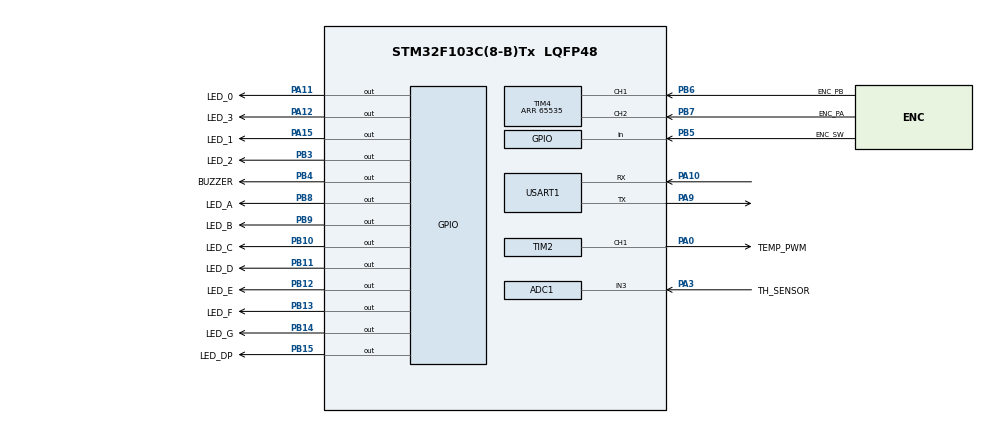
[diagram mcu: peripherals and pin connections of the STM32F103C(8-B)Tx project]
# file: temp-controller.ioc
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ADC1.Channel-2\#ChannelRegularConversion=ADC_CHANNEL_3
ADC1.ContinuousConvMode=ENABLE
ADC1.NbrOfConversion=1
ADC1.NbrOfConversionFlag=1
ADC1.Rank-2\#ChannelRegularConversion=1
ADC1.SamplingTime-2\#ChannelRegularConversion=ADC_SAMPLETIME_1CYCLE_5
ADC1.master=1
Mcu.Family=STM32F1
Mcu.Name=STM32F103C(8-B)Tx
Mcu.Package=LQFP48
NVIC.ADC1_2_IRQn=true\:0\:0\:false\:false\:true\:true\:true
NVIC.PriorityGroup=NVIC_PRIORITYGROUP_4
NVIC.TIM4_IRQn=true\:0\:0\:false\:false\:true\:true\:true
PA0-WKUP.GPIO_Label=TEMP_PWM
PA0-WKUP.Signal=S_TIM2_CH1_ETR
PA10.Mode=Asynchronous
PA10.Signal=USART1_RX
PA11.GPIO_Label=LED_0
PA11.Signal=GPIO_Output
PA12.GPIO_Label=LED_3
PA12.Signal=GPIO_Output
PA13.Mode=Serial_Wire
PA13.Signal=SYS_JTMS-SWDIO
PA14.Mode=Serial_Wire
PA14.Signal=SYS_JTCK-SWCLK
PA15.GPIO_Label=LED_1
PA15.Signal=GPIO_Output
PA3.GPIO_Label=TH_SENSOR
PA3.Signal=ADCx_IN3
PA9.Mode=Asynchronous
PA9.Signal=USART1_TX
PB10.GPIO_Label=LED_C
PB10.Signal=GPIO_Output
PB11.GPIO_Label=LED_D
PB11.Signal=GPIO_Output
PB12.GPIO_Label=LED_E
PB12.Signal=GPIO_Output
PB13.GPIO_Label=LED_F
PB13.Signal=GPIO_Output
PB14.GPIO_Label=LED_G
PB14.Signal=GPIO_Output
PB15.GPIO_Label=LED_DP
PB15.Signal=GPIO_Output
PB3.GPIO_Label=LED_2
PB3.Signal=GPIO_Output
PB4.GPIO_Label=BUZZER
PB4.Signal=GPIO_Output
PB5.GPIO_Label=ENC_SW
PB5.Signal=GPIO_Input
PB6.GPIO_Label=ENC_PB
PB6.GPIO_PuPd=GPIO_PULLUP
PB6.Signal=S_TIM4_CH1
PB7.GPIO_Label=ENC_PA
PB7.GPIO_PuPd=GPIO_PULLUP
PB7.Signal=S_TIM4_CH2
PB8.GPIO_Label=LED_A
PB8.Signal=GPIO_Output
PB9.GPIO_Label=LED_B
PB9.Signal=GPIO_Output
ProjectManager.HeapSize=0x200
ProjectManager.StackSize=0x400
ProjectManager.TargetToolchain=SW4STM32
RCC.APB1Freq_Value=8000000
RCC.APB2Freq_Value=8000000
SH.ADCx_IN3.0=ADC1_IN3,IN3
SH.S_TIM2_CH1_ETR.0=TIM2_CH1,PWM Generation1 CH1
SH.S_TIM4_CH1.0=TIM4_CH1,Encoder_Interface
SH.S_TIM4_CH2.0=TIM4_CH2,Encoder_Interface
TIM2.Channel-PWM\ Generation1\ CH1=TIM_CHANNEL_1
TIM2.Period=999
TIM2.Prescaler=79
TIM4.EncoderMode=TIM_ENCODERMODE_TI12
TIM4.Period=65535
USART1.VirtualMode=VM_ASYNC
VP_TIM2_VS_ClockSourceINT.Mode=Internal
board=custom

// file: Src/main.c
/* USER CODE BEGIN Header */
/**
  ******************************************************************************
  * @file           : main.c
  * @brief          : Main program body
  ******************************************************************************
  * @attention
  *
  * <h2><center>&copy; Copyright (c) 2019 STMicroelectronics.
  * All rights reserved.</center></h2>
  *
  * This software component is licensed by ST under BSD 3-Clause license,
  * the "License"; You may not use this file except in compliance with the
  * License. You may obtain a copy of the License at:
  *                        opensource.org/licenses/BSD-3-Clause
  *
  ******************************************************************************
  */
/* USER CODE END Header */

#include "main.h"
#include "adc.h"
#include "tim.h"
#include "usart.h"
#include "gpio.h"

/* USER CODE BEGIN Includes */
#include <Src/user_code/user_main.h>
/* USER CODE END Includes */

void SystemClock_Config(void);

int main(void)
{

  /* MCU Configuration--------------------------------------------------------*/

  /* Reset of all peripherals, Initializes the Flash interface and the Systick. */
  HAL_Init();

  /* Configure the system clock */
  SystemClock_Config();

  /* Initialize all configured peripherals */
  MX_GPIO_Init();
  MX_ADC1_Init();
  MX_TIM2_Init();
  MX_TIM4_Init();
  MX_USART1_UART_Init();
  /* USER CODE BEGIN 2 */

  user_main();

  /* USER CODE END 2 */

  /* Infinite loop */
  /* USER CODE BEGIN WHILE */
  while (1)
  {
//	  for(float i = 0; i <=99.99; i+=0.01){
//		  led_show(i);
//		  HAL_Delay(10);
//	  }
    /* USER CODE END WHILE */

  }
}

void SystemClock_Config(void)
{
  RCC_OscInitTypeDef RCC_OscInitStruct = {0};
  RCC_ClkInitTypeDef RCC_ClkInitStruct = {0};
  RCC_PeriphCLKInitTypeDef PeriphClkInit = {0};

  /** Initializes the CPU, AHB and APB busses clocks
  */
  RCC_OscInitStruct.OscillatorType = RCC_OSCILLATORTYPE_HSI;
  RCC_OscInitStruct.HSIState = RCC_HSI_ON;
  RCC_OscInitStruct.HSICalibrationValue = RCC_HSICALIBRATION_DEFAULT;
  RCC_OscInitStruct.PLL.PLLState = RCC_PLL_NONE;
  if (HAL_RCC_OscConfig(&RCC_OscInitStruct) != HAL_OK)
  {
    Error_Handler();
  }
  /** Initializes the CPU, AHB and APB busses clocks
  */
  RCC_ClkInitStruct.ClockType = RCC_CLOCKTYPE_HCLK|RCC_CLOCKTYPE_SYSCLK
                              |RCC_CLOCKTYPE_PCLK1|RCC_CLOCKTYPE_PCLK2;
  RCC_ClkInitStruct.SYSCLKSource = RCC_SYSCLKSOURCE_HSI;
  RCC_ClkInitStruct.AHBCLKDivider = RCC_SYSCLK_DIV1;
  RCC_ClkInitStruct.APB1CLKDivider = RCC_HCLK_DIV1;
  RCC_ClkInitStruct.APB2CLKDivider = RCC_HCLK_DIV1;

  if (HAL_RCC_ClockConfig(&RCC_ClkInitStruct, FLASH_LATENCY_0) != HAL_OK)
  {
    Error_Handler();
  }
  PeriphClkInit.PeriphClockSelection = RCC_PERIPHCLK_ADC;
  PeriphClkInit.AdcClockSelection = RCC_ADCPCLK2_DIV2;
  if (HAL_RCCEx_PeriphCLKConfig(&PeriphClkInit) != HAL_OK)
  {
    Error_Handler();
  }
}

void Error_Handler(void)
{
}

/************************ (C) COPYRIGHT STMicroelectronics *****END OF FILE****/
